VERSION ""

NS_ :

BS_:

BU_:
VAL_TABLE_ Alternative_Fuel_Mode_Enumeratio 0 "Not_in_Use" 1 "Flex_Fuel" 2 "Secondary_Fuel" ;
VAL_TABLE_ Warning_Source_Enumeration 23 "Exhaust_Temperature_Diagnostic" 35 "Boost_Control_Diagnostic" 36 "Coolant_Pressure_Sensor_Diagnostic" 21 "Exhaust_Lambda_Bank_1_Collector_Diagnostic" 24 "Throttle_Pedal_Sensor_Diagnostic" 25 "Throttle_Position_Sensor_Diagnostic" 26 "Throttle_Servo_Bank_1_Position_Sensor_Diagnostic" 27 "Throttle_Servo_Bank_2_Position_Sensor_Diagnostic" 37 "Inlet_Camshaft_Bank_1_Position_Diagnostic" 60 "Fuel_Cylinder_8_Secondary_Pin_Diagnostic" 64 "Fuel_Cylinder_12_Secondary_Pin_Diagnostic" 52 "Fuel_Cylinder_12_Primary_Pin_Diagnostic" 66 "CAN_Bus_2_Diagnostic" 65 "CAN_Bus_1_Diagnostic" 63 "Fuel_Cylinder_11_Secondary_Pin_Diagnostic" 38 "Inlet_Camshaft_Bank_2_Position_Diagnostic" 62 "Fuel_Cylinder_10_Secondary_Pin_Diagnostic" 30 "Fuel_Temperature_Sensor_Diagnostic" 17 "Brake_Vacuum_Pressure_Sensor_Diagnostic" 59 "Fuel_Cylinder_7_Secondary_Pin_Diagnostic" 18 "Inlet_Air_Temperature_Sensor_Diagnostic" 19 "Engine_Crankcase_Pressure_Sensor_Diagnostic" 20 "Engine_Oil_Temperature_Sensor_Diagnostic" 56 "Fuel_Cylinder_4_Secondary_Pin_Diagnostic" 48 "Fuel_Cylinder_8_Primary_Pin_Diagnostic" 49 "Fuel_Cylinder_9_Primary_Pin_Diagnostic" 45 "Fuel_Cylinder_5_Primary_Pin_Diagnostic" 50 "Fuel_Cylinder_10_Primary_Pin_Diagnostic" 51 "Fuel_Cylinder_11_Primary_Pin_Diagnostic" 57 "Fuel_Cylinder_5_Secondary_Pin_Diagnostic" 58 "Fuel_Cylinder_6_Secondary_Pin_Diagnostic" 14 "Engine_Oil_Pressure_Sensor_Diagnostic" 11 "Coolant_Pressure_Warning" 13 "Inlet_Manifold_Pressure_Sensor_Diagnostic" 12 "Engine_Speed_Warning" 28 "Boost_Pressure_Sensor_Diagnostic" 39 "Exhaust_Camshaft_Bank_1_Position_Diagnostic" 67 "CAN_Bus_3_Diagnostic" 70 "GPS_Diagnostic" 41 "Fuel_Cylinder_1_Primary_Pin_Diagnostic" 42 "Fuel_Cylinder_2_Primary_Pin_Diagnostic" 43 "Fuel_Cylinder_3_Primary_Pin_Diagnostic" 44 "Fuel_Cylinder_4_Primary_Pin_Diagnostic" 33 "Throttle_Servo_Bank_1_Diagnostic" 34 "Throttle_Servo_Bank_2_Diagnostic" 32 "Fuel_Closed_Loop_Diagnostic" 31 "Ambient_Pressure_Sensor_Diagnostic" 53 "Fuel_Cylinder_1_Secondary_Pin_Diagnostic" 55 "Fuel_Cylinder_3_Secondary_Pin_Diagnostic" 22 "Exhaust_Lambda_Bank_2_Collector_Diagnostic" 0 "None" 16 "Fuel_Pressure_Sensor_Diagnostic" 54 "Fuel_Cylinder_2_Secondary_Pin_Diagnostic" 2 "Knock_Warning" 3 "Engine_Crankcase_Pressure_Warning" 4 "Fuel_Pressure_Warning" 6 "Coolant_Temperature_Warning" 7 "Inlet_Air_Temperature_Warning" 8 "Engine_Oil_Temperature_Warning" 61 "Fuel_Cylinder_9_Secondary_Pin_Diagnostic" 10 "Exhaust_Temperature_Warning" 9 "Exhaust_Lambda_Warning" 46 "Fuel_Cylinder_6_Primary_Pin_Diagnostic" 47 "Fuel_Cylinder_7_Primary_Pin_Diagnostic" 15 "Coolant_Temperature_Sensor_Diagnostic" 40 "Exhaust_Camshaft_Bank_2_Position_Diagnostic" 68 "RS232_Diagnostic" 69 "Engine_Speed_Reference_Diagnostic" 1 "Engine_Oil_Pressure_Warning" 71 "Engine_Speed_Reference_State" 72 "Vehicle_Acceleration_Lateral_Sensor_Diagnostic" 5 "Alternative_Fuel_Pressure_Warning" 29 "Fuel_Composition_Sensor_Diagnostic" ;
VAL_TABLE_ Engine_State_Enumeration 0 "Startup" 1 "Stop" 2 "Run" 3 "Crank" ;
VAL_TABLE_ Fuel_Pump_Relay_State_Enumeratio 0 "Off" 1 "On" 2 "Prime" 3 "Hold" 4 "Test" ;
VAL_TABLE_ Anti_Lag_State_Enumeration 1 "Armed" 0 "Disabled" 2 "Enabled" 3 "Recover" ;
VAL_TABLE_ Mode_Enumeration 0 "Disabled" 1 "Enabled" ;
VAL_TABLE_ Boost_Aim_State_Enumeration 0 "Normal" 1 "Anti_Lag" 2 "Launch" ;
VAL_TABLE_ Engine_Overrun_State_Enumeration 0 "Disabled" 1 "Retard_Ignition" 2 "Enabled" 3 "Advance_Ignition" ;
VAL_TABLE_ Knock_State_Enumeration 0 "Disabled" 1 "Enabled" 2 "Transient" ;
VAL_TABLE_ Throttle_Aim_State_Enumeration 5 "Test" 1 "Idle" 0 "Pedal" 2 "Anti_Lag" 3 "Throttle_Limit" 4 "Gear_Shift" ;
VAL_TABLE_ Fuel_Closed_Loop_State_Enumerati -1 "Fault" 0 "Disabled" 1 "Shutdown" 2 "Wait" 3 "Sample" ;
VAL_TABLE_ Reference_State 0 "Open" 1 "Initialise" 2 "Stall" 3 "First Edge" 4 "First Period" 5 "Search" 6 "Pattern Lock" 7 "Cycle Lock" 8 "Error" 9 "Exit" 10 "Test" ;
VAL_TABLE_ Gear_Enumeration -2 "Default" -1 "Reverse" 0 "Neutral" 1 "First" 2 "Second" 3 "Third" 4 "Fourth" 5 "Fifth" 6 "Sixth" 7 "Seventh" ;
VAL_TABLE_ Fuel_State_Enumeration 5 "Cut_Cylinder_2_Test" 1 "Enabled" 2 "Cut_Bank_1_Test" 3 "Cut_Bank_2_Test" 4 "Cut_Cylinder_1_Test" 6 "Cut_Cylinder_3_Test" 7 "Cut_Cylinder_4_Test" 8 "Cut_Cylinder_5_Test" 9 "Cut_Cylinder_6_Test" 10 "Cut_Cylinder_7_Test" 11 "Cut_Cylinder_8_Test" 12 "Cut_Cylinder_9_Test" 13 "Cut_Cylinder_10_Test" 14 "Cut_Cylinder_11_Test" 15 "Cut_Cylinder_12_Test" 0 "Disabled" ;
VAL_TABLE_ Engine_Speed_Limit_State_Enumera 0 "Maximum" 2 "Throttle_Servo_Fault" 3 "Coolant_Temperature" 7 "Engine_Output_Test" 4 "Traction_Control" 5 "Launch" 6 "Vehicle_Speed_Limit" 1 "Engine_Load_Average" 8 "Anti_Lag" 10 "Coolant_Temperature_Warning" 11 "Coolant_Pressure_Warning" 12 "Engine_Speed_Warning" 13 "Engine_Oil_Temperature_Warning" 14 "Engine_Oil_Pressure_Warning" 15 "Engine_Crankcase_Pressure_Warning" 16 "Fuel_Pressure_Warning" 9 "Gear_Shift" 17 "Inlet_Air_Temperature_Warning" 18 "Exhaust_Lambda_Warning" 19 "Exhaust_Temperature_Warning" 20 "Experimental_Reference_Mode" 21 "Alternative_Fuel_Pressure_Warning" 22 "Boost_Servo_Fault" ;
VAL_TABLE_ Anti_Lag_Diagnostic_Enumeration 3 "Exhaust_Temperature_High" 2 "Time_Limit" 4 "Coolant_Temperature_High" 0 "Not_in_Use" 1 "OK" ;
VAL_TABLE_ Launch_Diagnostic_Enumeration 0 "Not_in_Use" 1 "OK" 2 "Exhaust_Temperature_High" 3 "Coolant_Temperature_High" ;
VAL_TABLE_ Boost_Control_Diagnostic_Enumera -1 "Maximum" 0 "Not_in_Use" 1 "Off" 2 "Active" 3 "Under_Margin" 4 "Over_Margin" 5 "Test" ;
VAL_TABLE_ Fuel_Cut_State_Enumeration 0 "None" 1 "Anti_Lag" 2 "Engine_Overrun" 3 "Flooded_Throttle_Position" 4 "Boost_Control_Diagnostic" 5 "Gear_Shift" 6 "Engine_Speed_Limit" ;
VAL_TABLE_ Fuel_Closed_Loop_Diagnostic_Enum -1 "Control_Failure" 0 "Sensor_Unavailable" 1 "OK" 2 "Single_Sensor" ;
VAL_TABLE_ Brake_State_Enumeration -1 "Sensor_Fault" 0 "Unknown" 1 "Off" 2 "On" ;
VAL_TABLE_ Nine_Position_Switch_State_Enume -1 "Default" 1 "One" 2 "Two" 3 "Three" 4 "Four" 5 "Five" 6 "Six" 7 "Seven" 8 "Eight" 9 "Nine" 0 "Zero" ;
VAL_TABLE_ Sensor_Diagnostic_Enumeration -3 "Communications_Timeout" -2 "Low_Fault" -1 "High_Fault" 0 "Not_in_Use" 1 "OK" 2 "Low_Warning" 3 "High_Warning" 4 "Translation_Minimum" 5 "Translation_Maximum" ;
VAL_TABLE_ Ignition_Timing_State_Enumeratio 3 "Limit_Advance" 4 "Limit_Retard" 0 "Normal" 2 "Check_Timing" 1 "Cranking" 7 "Launch" 5 "Idle" 6 "Engine_Overrun" 8 "Gear_Shift" 9 "Anti_Lag" ;
VAL_TABLE_ Ignition_Cut_State_Enumeration 0 "None" 1 "Anti_Lag" 2 "Gear_Shift" 3 "Engine_Speed_Limit" ;

BO_ 3221225472 VECTOR__INDEPENDENT_SIG_MSG: 0 Vector__XXX
 SG_ Steering_Angle_ADR : 0|16@0- (0.1,0) [0|0] "deg" Vector__XXX
 SG_ Wheel_Speed_Rear_Right_ADR : 0|16@0+ (0.1,0) [0|340] "km/h" Vector__XXX
 SG_ Wheel_Speed_Rear_Left_ADR : 0|16@0+ (0.1,0) [0|340] "km/h" Vector__XXX
 SG_ Wheel_Speed_Front_Right_ADR : 0|16@0+ (0.1,0) [0|340] "km/h" Vector__XXX
 SG_ Wheel_Speed_Front_Left_ADR : 0|16@0+ (0.1,0) [0|340] "km/h" Vector__XXX
 SG_ Brake_Pressure_Rear_ADR : 0|16@0+ (1,0) [0|65535] "kPa" Vector__XXX
 SG_ Brake_Pressure_Front_ADR : 0|16@0+ (1,0) [0|65535] "kPa" Vector__XXX
 SG_ Throttle_Position_ADR : 0|16@0+ (0.1,0) [0|100] "%" Vector__XXX
 SG_ Engine_Speed_ADR : 0|16@0+ (6,0) [0|393210] "RPM" Vector__XXX

BO_ 1697 M1_General_0x6A1: 8 Vector__XXX
 SG_ Auxillary_Output_5_Duty_Cycle : 7|16@0+ (0.1,0) [0|0] "%" Vector__XXX

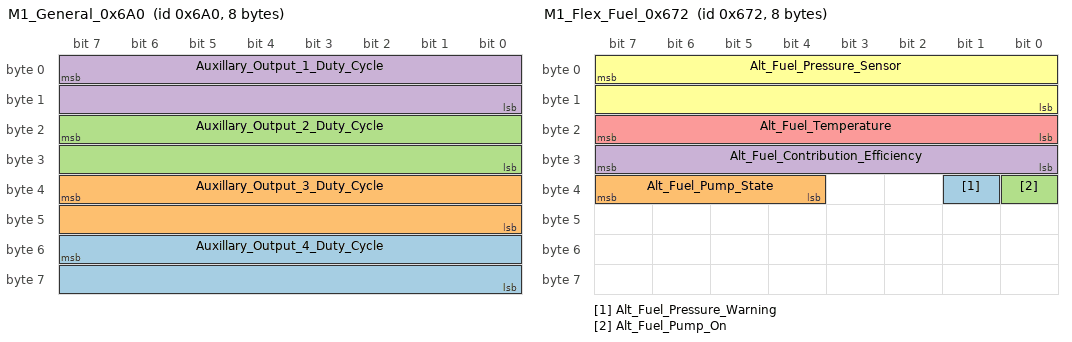
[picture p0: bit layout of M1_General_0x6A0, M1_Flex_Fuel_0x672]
BO_ 1696 M1_General_0x6A0: 8 Vector__XXX
 SG_ Auxillary_Output_4_Duty_Cycle : 55|16@0- (0.1,0) [0|0] "%" Vector__XXX
 SG_ Auxillary_Output_3_Duty_Cycle : 39|16@0- (0.1,0) [0|0] "%" Vector__XXX
 SG_ Auxillary_Output_2_Duty_Cycle : 23|16@0- (0.1,0) [0|0] "%" Vector__XXX
 SG_ Auxillary_Output_1_Duty_Cycle : 7|16@0- (0.1,0) [0|0] "%" Vector__XXX

BO_ 1650 M1_Flex_Fuel_0x672: 8 Vector__XXX
 SG_ Alt_Fuel_Pressure_Warning : 33|1@0+ (1,0) [0|1] "" Vector__XXX
 SG_ Alt_Fuel_Pump_State : 39|4@0- (1,0) [-8|7] "" Vector__XXX
 SG_ Alt_Fuel_Pump_On : 32|1@0+ (1,0) [0|1] "" Vector__XXX
 SG_ Alt_Fuel_Contribution_Efficiency : 31|8@0+ (1,0) [0|0] "%" Vector__XXX
 SG_ Alt_Fuel_Temperature : 23|8@0+ (1,-40) [-40|215] "C" Vector__XXX
 SG_ Alt_Fuel_Pressure_Sensor : 7|16@0+ (0.1,0) [0|1000] "kPa" Vector__XXX

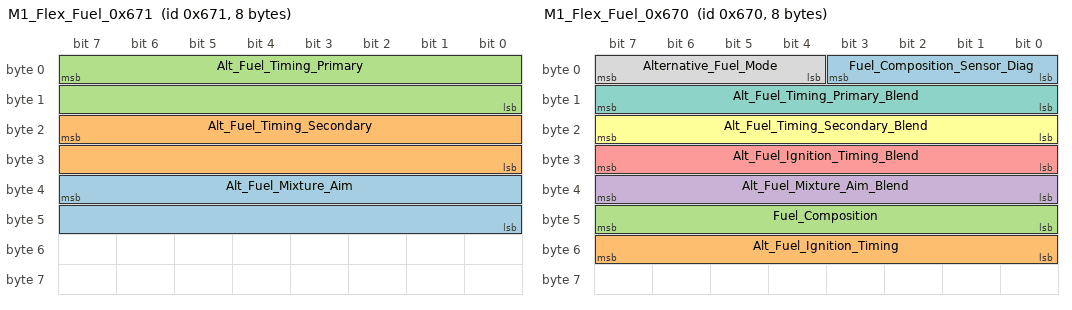
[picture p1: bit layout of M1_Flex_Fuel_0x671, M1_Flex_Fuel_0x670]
BO_ 1649 M1_Flex_Fuel_0x671: 8 Vector__XXX
 SG_ Alt_Fuel_Mixture_Aim : 39|16@0+ (0.01,0) [0|2] "LA" Vector__XXX
 SG_ Alt_Fuel_Timing_Secondary : 23|16@0- (0.1,0) [-720|720] "deg" Vector__XXX
 SG_ Alt_Fuel_Timing_Primary : 7|16@0- (0.1,0) [-720|720] "deg" Vector__XXX

BO_ 1648 M1_Flex_Fuel_0x670: 8 Vector__XXX
 SG_ Fuel_Composition_Sensor_Diag : 3|4@0- (1,0) [-8|7] "" Vector__XXX
 SG_ Alt_Fuel_Ignition_Timing : 55|8@0- (0.5,0) [0|0] "deg" Vector__XXX
 SG_ Fuel_Composition : 47|8@0+ (1,0) [0|0] "%" Vector__XXX
 SG_ Alt_Fuel_Mixture_Aim_Blend : 39|8@0+ (1,0) [0|0] "%" Vector__XXX
 SG_ Alt_Fuel_Ignition_Timing_Blend : 31|8@0+ (1,0) [0|0] "%" Vector__XXX
 SG_ Alt_Fuel_Timing_Secondary_Blend : 23|8@0+ (1,0) [0|0] "%" Vector__XXX
 SG_ Alt_Fuel_Timing_Primary_Blend : 15|8@0+ (1,0) [0|0] "%" Vector__XXX
 SG_ Alternative_Fuel_Mode : 7|4@0- (1,0) [0|0] "" Vector__XXX

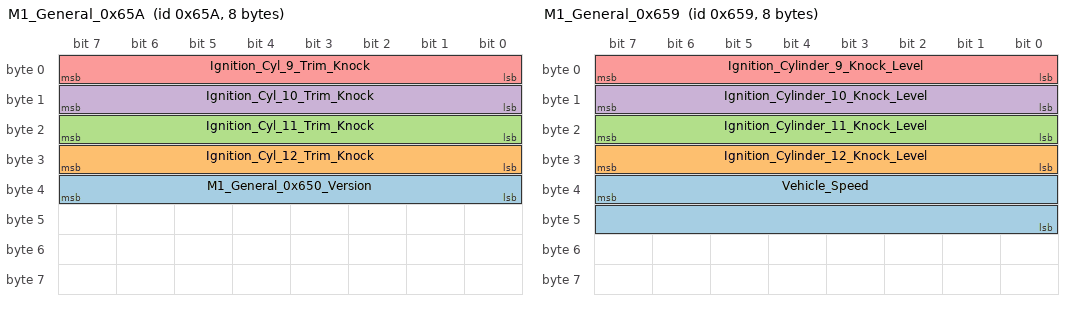
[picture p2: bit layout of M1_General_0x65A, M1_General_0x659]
BO_ 1626 M1_General_0x65A: 8 Vector__XXX
 SG_ M1_General_0x650_Version : 39|8@0+ (1,0) [0|0] "" Vector__XXX
 SG_ Ignition_Cyl_12_Trim_Knock : 31|8@0+ (0.1,0) [0|25.5] "deg" Vector__XXX
 SG_ Ignition_Cyl_11_Trim_Knock : 23|8@0+ (0.1,0) [0|25.5] "deg" Vector__XXX
 SG_ Ignition_Cyl_10_Trim_Knock : 15|8@0+ (0.1,0) [0|25.5] "deg" Vector__XXX
 SG_ Ignition_Cyl_9_Trim_Knock : 7|8@0+ (0.1,0) [0|25.5] "deg" Vector__XXX

BO_ 1625 M1_General_0x659: 8 Vector__XXX
 SG_ Vehicle_Speed : 39|16@0+ (0.1,0) [0|6553.5] "km/h" Vector__XXX
 SG_ Ignition_Cylinder_12_Knock_Level : 31|8@0+ (1,0) [0|200] "%" Vector__XXX
 SG_ Ignition_Cylinder_11_Knock_Level : 23|8@0+ (1,0) [0|200] "%" Vector__XXX
 SG_ Ignition_Cylinder_10_Knock_Level : 15|8@0+ (1,0) [0|200] "%" Vector__XXX
 SG_ Ignition_Cylinder_9_Knock_Level : 7|8@0+ (1,0) [0|200] "%" Vector__XXX

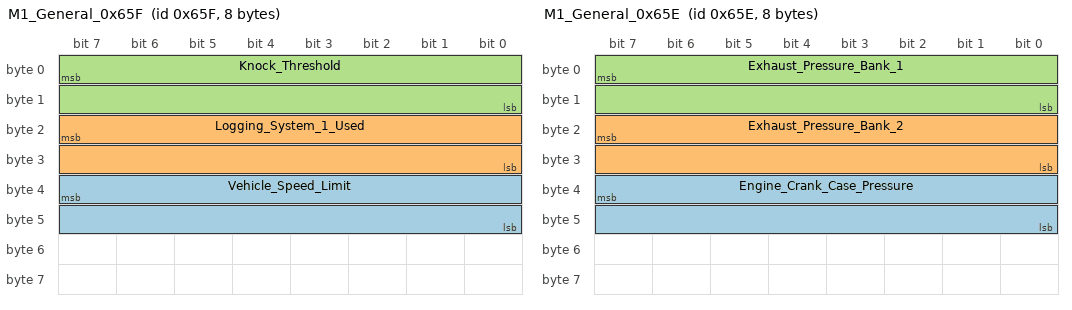
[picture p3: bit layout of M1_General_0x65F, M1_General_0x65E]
BO_ 1631 M1_General_0x65F: 8 Vector__XXX
 SG_ Vehicle_Speed_Limit : 39|16@0+ (0.1,0) [0|6553.5] "km/h" Vector__XXX
 SG_ Logging_System_1_Used : 23|16@0+ (0.1,0) [0|0] "%" Vector__XXX
 SG_ Knock_Threshold : 7|16@0+ (0.1,0) [0|200] "%" Vector__XXX

BO_ 1630 M1_General_0x65E: 8 Vector__XXX
 SG_ Engine_Crank_Case_Pressure : 39|16@0- (0.1,0) [0|24000] "kPa" Vector__XXX
 SG_ Exhaust_Pressure_Bank_2 : 23|16@0- (0.1,0) [0|24000] "kPa" Vector__XXX
 SG_ Exhaust_Pressure_Bank_1 : 7|16@0- (0.1,0) [0|24000] "kPa" Vector__XXX

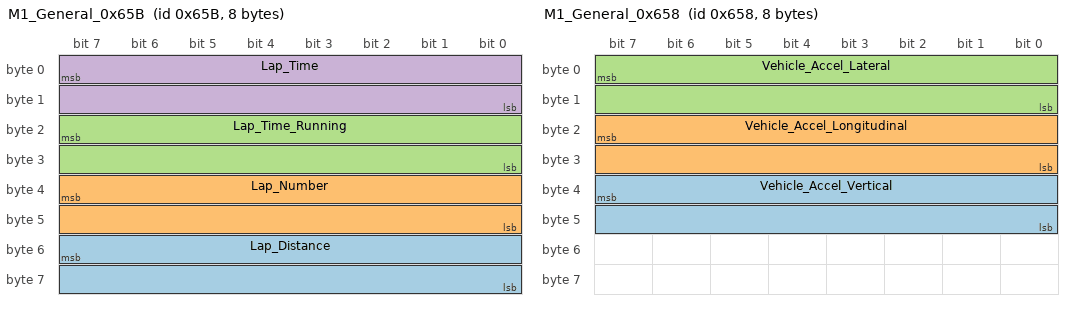
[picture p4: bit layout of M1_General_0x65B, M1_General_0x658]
BO_ 1627 M1_General_0x65B: 8 Vector__XXX
 SG_ Lap_Distance : 55|16@0+ (1,0) [0|0] "m" Vector__XXX
 SG_ Lap_Number : 39|16@0+ (1,0) [0|0] "" Vector__XXX
 SG_ Lap_Time_Running : 23|16@0+ (0.01,0) [0|0] "s" Vector__XXX
 SG_ Lap_Time : 7|16@0+ (0.01,0) [0|0] "s" Vector__XXX

BO_ 1624 M1_General_0x658: 8 Vector__XXX
 SG_ Vehicle_Accel_Vertical : 39|16@0- (0.001,0) [0|0] "g" Vector__XXX
 SG_ Vehicle_Accel_Longitudinal : 23|16@0- (0.001,0) [0|0] "g" Vector__XXX
 SG_ Vehicle_Accel_Lateral : 7|16@0- (0.001,0) [0|0] "g" Vector__XXX

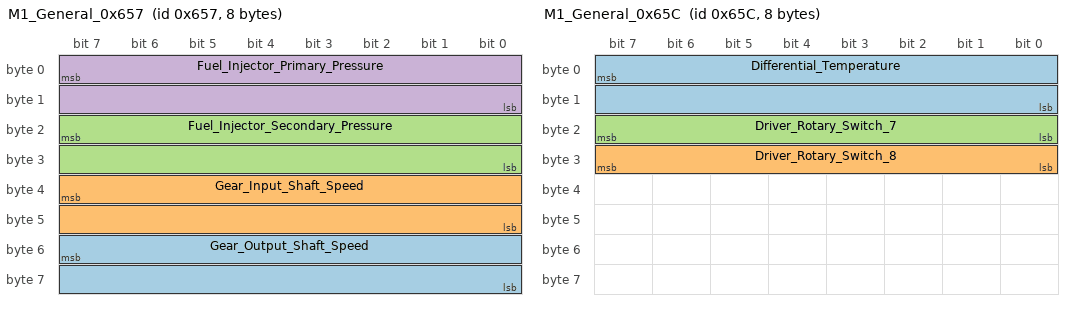
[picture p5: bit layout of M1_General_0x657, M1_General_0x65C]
BO_ 1623 M1_General_0x657: 8 Vector__XXX
 SG_ Gear_Output_Shaft_Speed : 55|16@0+ (1,0) [0|0] "RPM" Vector__XXX
 SG_ Gear_Input_Shaft_Speed : 39|16@0+ (1,0) [0|0] "RPM" Vector__XXX
 SG_ Fuel_Injector_Secondary_Pressure : 23|16@0- (0.1,0) [0|24000] "kPa" Vector__XXX
 SG_ Fuel_Injector_Primary_Pressure : 7|16@0- (0.1,0) [0|24000] "kPa" Vector__XXX

BO_ 1628 M1_General_0x65C: 8 Vector__XXX
 SG_ Differential_Temperature : 7|16@0- (0.1,0) [-30|160] "C" Vector__XXX
 SG_ Driver_Rotary_Switch_8 : 31|8@0- (1,0) [0|0] "" Vector__XXX
 SG_ Driver_Rotary_Switch_7 : 23|8@0- (1,0) [0|0] "" Vector__XXX

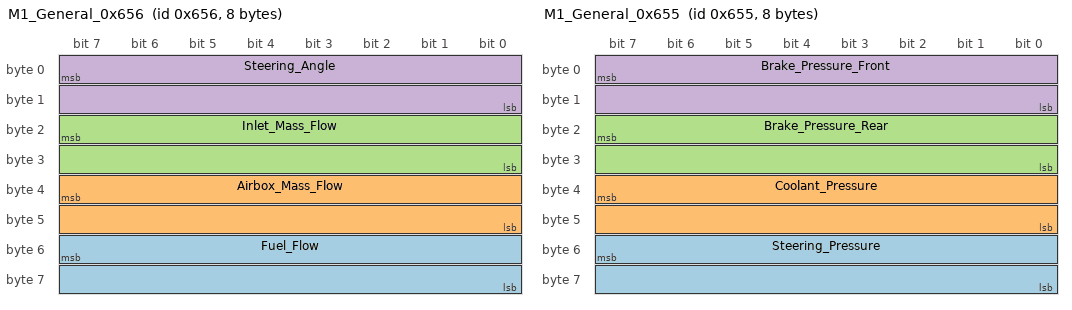
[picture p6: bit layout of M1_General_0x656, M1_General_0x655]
BO_ 1622 M1_General_0x656: 8 Vector__XXX
 SG_ Fuel_Flow : 55|16@0+ (0.01,0) [0|0] "ml/s" Vector__XXX
 SG_ Airbox_Mass_Flow : 39|16@0+ (0.1,0) [0|0] "g/s" Vector__XXX
 SG_ Inlet_Mass_Flow : 23|16@0+ (0.1,0) [0|0] "g/s" Vector__XXX
 SG_ Steering_Angle : 7|16@0- (0.1,0) [0|0] "deg" Vector__XXX

BO_ 1621 M1_General_0x655: 8 Vector__XXX
 SG_ Steering_Pressure : 55|16@0- (1,0) [-32768|32767] "kPa" Vector__XXX
 SG_ Coolant_Pressure : 39|16@0- (0.1,0) [-3276.8|3276.7] "kPa" Vector__XXX
 SG_ Brake_Pressure_Rear : 23|16@0- (1,0) [-32768|32767] "kPa" Vector__XXX
 SG_ Brake_Pressure_Front : 7|16@0- (1,0) [-32768|32767] "kPa" Vector__XXX

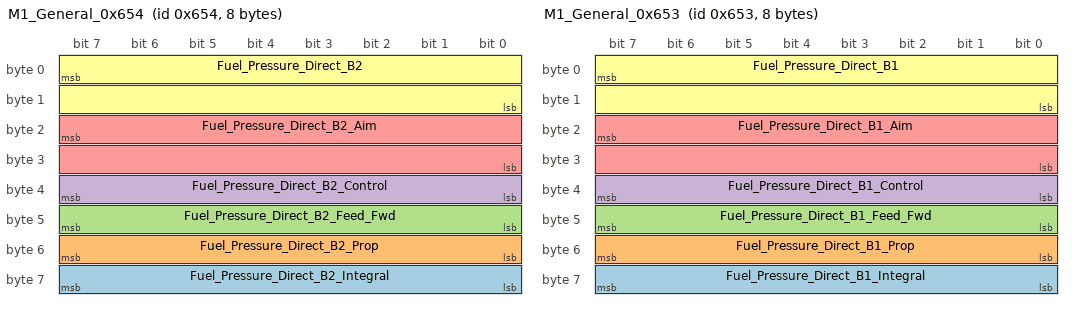
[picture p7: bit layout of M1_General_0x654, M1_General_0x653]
BO_ 1620 M1_General_0x654: 8 Vector__XXX
 SG_ Fuel_Pressure_Direct_B2_Integral : 63|8@0- (1,0) [-128|127] "%" Vector__XXX
 SG_ Fuel_Pressure_Direct_B2_Prop : 55|8@0- (1,0) [-128|127] "%" Vector__XXX
 SG_ Fuel_Pressure_Direct_B2_Feed_Fwd : 47|8@0- (1,0) [-128|127] "%" Vector__XXX
 SG_ Fuel_Pressure_Direct_B2_Control : 39|8@0+ (0.5,0) [0|100] "%" Vector__XXX
 SG_ Fuel_Pressure_Direct_B2_Aim : 23|16@0+ (1,0) [0|24000] "kPa" Vector__XXX
 SG_ Fuel_Pressure_Direct_B2 : 7|16@0+ (1,0) [0|24000] "kPa" Vector__XXX

BO_ 1619 M1_General_0x653: 8 Vector__XXX
 SG_ Fuel_Pressure_Direct_B1_Integral : 63|8@0- (1,0) [-128|127] "%" Vector__XXX
 SG_ Fuel_Pressure_Direct_B1_Prop : 55|8@0- (1,0) [-128|127] "%" Vector__XXX
 SG_ Fuel_Pressure_Direct_B1_Feed_Fwd : 47|8@0- (1,0) [-128|127] "%" Vector__XXX
 SG_ Fuel_Pressure_Direct_B1_Control : 39|8@0+ (0.5,0) [0|100] "%" Vector__XXX
 SG_ Fuel_Pressure_Direct_B1_Aim : 23|16@0+ (1,0) [0|24000] "kPa" Vector__XXX
 SG_ Fuel_Pressure_Direct_B1 : 7|16@0+ (1,0) [0|24000] "kPa" Vector__XXX

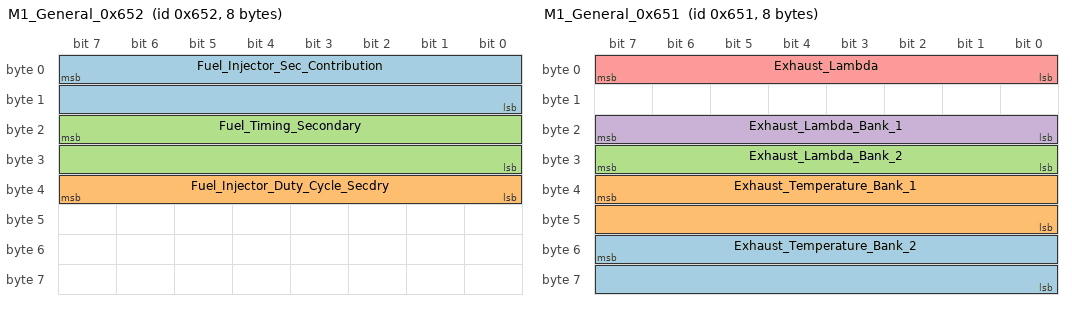
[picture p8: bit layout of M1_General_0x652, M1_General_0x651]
BO_ 1618 M1_General_0x652: 8 Vector__XXX
 SG_ Fuel_Injector_Sec_Contribution : 7|16@0+ (0.1,0) [0|100] "%" Vector__XXX
 SG_ Fuel_Injector_Duty_Cycle_Secdry : 39|8@0+ (1,0) [0|100] "%" Vector__XXX
 SG_ Fuel_Timing_Secondary : 23|16@0- (0.1,0) [-720|720] "deg" Vector__XXX

BO_ 1617 M1_General_0x651: 8 Vector__XXX
 SG_ Exhaust_Temperature_Bank_2 : 55|16@0+ (0.1,0) [0|1200] "C" Vector__XXX
 SG_ Exhaust_Temperature_Bank_1 : 39|16@0+ (0.1,0) [0|1200] "C" Vector__XXX
 SG_ Exhaust_Lambda_Bank_2 : 31|8@0+ (0.01,0) [0|0] "LA" Vector__XXX
 SG_ Exhaust_Lambda_Bank_1 : 23|8@0+ (0.01,0) [0|0] "LA" Vector__XXX
 SG_ Exhaust_Lambda : 7|8@0+ (0.01,0) [0|0] "LA" Vector__XXX

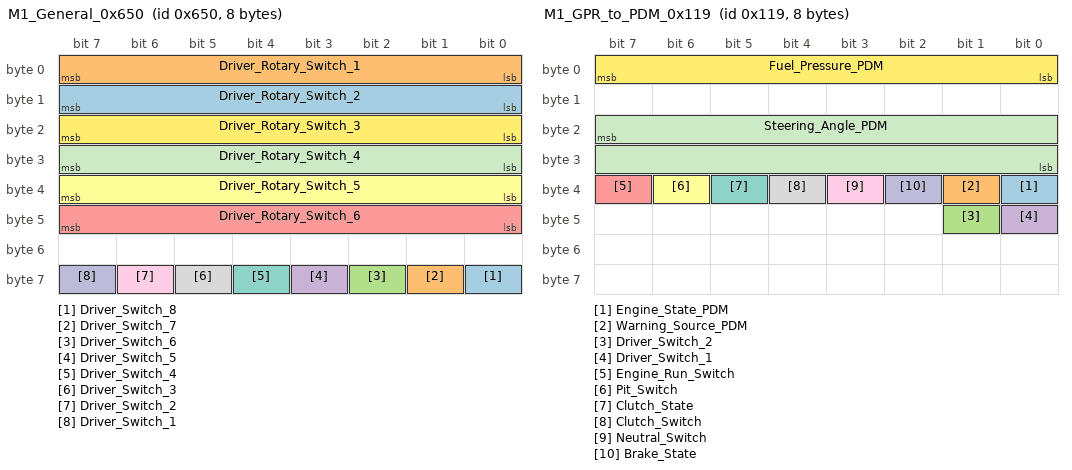
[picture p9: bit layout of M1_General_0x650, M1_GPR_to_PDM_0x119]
BO_ 1616 M1_General_0x650: 8 Vector__XXX
 SG_ Driver_Switch_8 : 56|1@0+ (1,0) [0|0] "" Vector__XXX
 SG_ Driver_Switch_7 : 57|1@0+ (1,0) [0|0] "" Vector__XXX
 SG_ Driver_Switch_6 : 58|1@0+ (1,0) [0|0] "" Vector__XXX
 SG_ Driver_Switch_5 : 59|1@0+ (1,0) [0|0] "" Vector__XXX
 SG_ Driver_Rotary_Switch_6 : 47|8@0- (1,0) [0|0] "" Vector__XXX
 SG_ Driver_Rotary_Switch_5 : 39|8@0- (1,0) [0|0] "" Vector__XXX
 SG_ Driver_Switch_4 : 60|1@0+ (1,0) [0|0] "" Vector__XXX
 SG_ Driver_Switch_3 : 61|1@0+ (1,0) [0|0] "" Vector__XXX
 SG_ Driver_Switch_2 : 62|1@0+ (1,0) [0|1] "" Vector__XXX
 SG_ Driver_Switch_1 : 63|1@0+ (1,0) [0|1] "" Vector__XXX
 SG_ Driver_Rotary_Switch_4 : 31|8@0- (1,0) [0|0] "" Vector__XXX
 SG_ Driver_Rotary_Switch_3 : 23|8@0- (1,0) [0|0] "" Vector__XXX
 SG_ Driver_Rotary_Switch_2 : 15|8@0- (1,0) [0|0] "" Vector__XXX
 SG_ Driver_Rotary_Switch_1 : 7|8@0- (1,0) [0|0] "" Vector__XXX

BO_ 1152 M1_LTC_Enable: 8 Vector__XXX

BO_ 282 M1_GPR_to_PDM_0x11A: 3 Vector__XXX
 SG_ PDM_Byte_2_Mask_80 : 23|1@0+ (1,0) [0|0] "" Vector__XXX
 SG_ PDM_Byte_2_Mask_40 : 22|1@0+ (1,0) [0|0] "" Vector__XXX
 SG_ PDM_Byte_2_Mask_20 : 21|1@0+ (1,0) [0|0] "" Vector__XXX
 SG_ PDM_Byte_2_Mask_10 : 20|1@0+ (1,0) [0|0] "" Vector__XXX
 SG_ PDM_Byte_2_Mask_08 : 19|1@0+ (1,0) [0|0] "" Vector__XXX
 SG_ PDM_Byte_2_Mask_04 : 18|1@0+ (1,0) [0|0] "" Vector__XXX
 SG_ PDM_Byte_2_Mask_02 : 17|1@0+ (1,0) [0|0] "" Vector__XXX
 SG_ PDM_Byte_2_Mask_01 : 16|1@0+ (1,0) [0|0] "" Vector__XXX
 SG_ PDM_Byte_1_Mask_80 : 15|1@0+ (1,0) [0|0] "" Vector__XXX
 SG_ PDM_Byte_1_Mask_40 : 14|1@0+ (1,0) [0|0] "" Vector__XXX
 SG_ PDM_Byte_1_Mask_20 : 13|1@0+ (1,0) [0|0] "" Vector__XXX
 SG_ PDM_Byte_1_Mask_10 : 12|1@0+ (1,0) [0|0] "" Vector__XXX
 SG_ PDM_Byte_1_Mask_08 : 11|1@0+ (1,0) [0|0] "" Vector__XXX
 SG_ PDM_Byte_1_Mask_04 : 10|1@0+ (1,0) [0|0] "" Vector__XXX
 SG_ PDM_Byte_1_Mask_02 : 9|1@0+ (1,0) [0|0] "" Vector__XXX
 SG_ PDM_Byte_1_Mask_01 : 8|1@0+ (1,0) [0|0] "" Vector__XXX
 SG_ PDM_Byte_0_Mask_80 : 7|1@0+ (1,0) [0|0] "" Vector__XXX
 SG_ PDM_Byte_0_Mask_40 : 6|1@0+ (1,0) [0|0] "" Vector__XXX
 SG_ PDM_Byte_0_Mask_20 : 5|1@0+ (1,0) [0|0] "" Vector__XXX
 SG_ PDM_Byte_0_Mask_10 : 4|1@0+ (1,0) [0|0] "" Vector__XXX
 SG_ PDM_Byte_0_Mask_08 : 3|1@0+ (1,0) [0|0] "" Vector__XXX
 SG_ PDM_Byte_0_Mask_04 : 2|1@0+ (1,0) [0|0] "" Vector__XXX
 SG_ PDM_Byte_0_Mask_02 : 1|1@0+ (1,0) [0|0] "" Vector__XXX
 SG_ PDM_Byte_0_Mask_01 : 0|1@0+ (1,0) [0|0] "" Vector__XXX

BO_ 281 M1_GPR_to_PDM_0x119: 8 Vector__XXX
 SG_ Engine_State_PDM : 32|1@0+ (1,0) [0|1] "" Vector__XXX
 SG_ Warning_Source_PDM : 33|1@0+ (1,0) [0|1] "" Vector__XXX
 SG_ Driver_Switch_2 : 41|1@0+ (1,0) [0|1] "" Vector__XXX
 SG_ Driver_Switch_1 : 40|1@0+ (1,0) [0|1] "" Vector__XXX
 SG_ Engine_Run_Switch : 39|1@0+ (1,0) [0|1] "" Vector__XXX
 SG_ Pit_Switch : 38|1@0+ (1,0) [0|1] "" Vector__XXX
 SG_ Clutch_State : 37|1@0+ (1,0) [0|1] "" Vector__XXX
 SG_ Clutch_Switch : 36|1@0+ (1,0) [0|1] "" Vector__XXX
 SG_ Neutral_Switch : 35|1@0+ (1,0) [0|1] "" Vector__XXX
 SG_ Brake_State : 34|1@0+ (1,0) [0|1] "" Vector__XXX
 SG_ Steering_Angle_PDM : 23|16@0- (0.1,0) [-3276|3276] "deg" Vector__XXX
 SG_ Fuel_Pressure_PDM : 7|8@0+ (10,0) [0|2550] "kPa" Vector__XXX

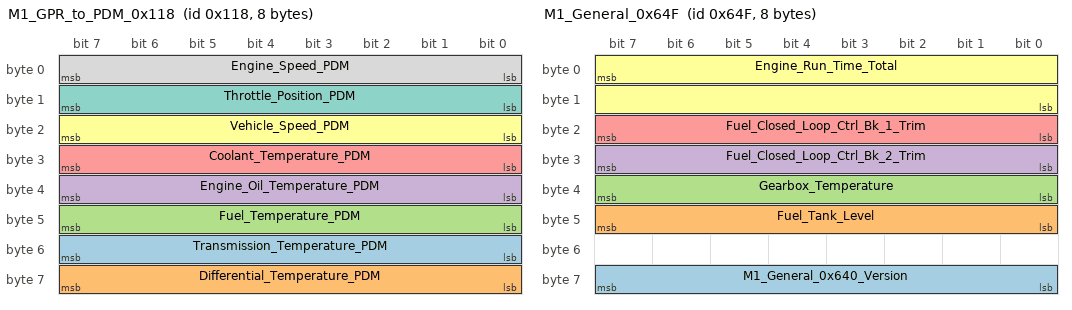
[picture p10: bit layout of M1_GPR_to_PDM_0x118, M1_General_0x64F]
BO_ 280 M1_GPR_to_PDM_0x118: 8 Vector__XXX
 SG_ Transmission_Temperature_PDM : 55|8@0+ (1,0) [0|255] "C" Vector__XXX
 SG_ Differential_Temperature_PDM : 63|8@0+ (1,0) [0|255] "C" Vector__XXX
 SG_ Fuel_Temperature_PDM : 47|8@0+ (1,0) [0|255] "C" Vector__XXX
 SG_ Engine_Oil_Temperature_PDM : 39|8@0+ (1,0) [0|255] "C" Vector__XXX
 SG_ Coolant_Temperature_PDM : 31|8@0+ (1,0) [0|255] "C" Vector__XXX
 SG_ Vehicle_Speed_PDM : 23|8@0+ (1,0) [0|255] "km/h" Vector__XXX
 SG_ Throttle_Position_PDM : 15|8@0+ (1,0) [0|255] "%" Vector__XXX
 SG_ Engine_Speed_PDM : 7|8@0+ (100,0) [0|25500] "RPM" Vector__XXX

BO_ 1615 M1_General_0x64F: 8 Vector__XXX
 SG_ M1_General_0x640_Version : 63|8@0+ (1,0) [0|0] "" Vector__XXX
 SG_ Fuel_Tank_Level : 47|8@0+ (1,0) [0|255] "l" Vector__XXX
 SG_ Gearbox_Temperature : 39|8@0+ (1,-40) [-40|215] "C" Vector__XXX
 SG_ Fuel_Closed_Loop_Ctrl_Bk_2_Trim : 31|8@0+ (0.005,0) [0|1.275] "ratio" Vector__XXX
 SG_ Fuel_Closed_Loop_Ctrl_Bk_1_Trim : 23|8@0+ (0.005,0) [0|1.275] "ratio" Vector__XXX
 SG_ Engine_Run_Time_Total : 7|16@0+ (0.1,0) [0|6553.5] "hour" Vector__XXX

BO_ 1614 M1_General_0x64E: 8 Vector__XXX
 SG_ Driver_Wheel_Circumference_Sw : 43|1@0+ (1,0) [0|0] "" Vector__XXX
 SG_ Driver_Trans_Brake_Bump_Sw : 44|1@0+ (1,0) [0|0] "" Vector__XXX
 SG_ Driver_Throttle_Pedal_Trans_Sw : 45|1@0+ (1,0) [0|0] "" Vector__XXX
 SG_ Driver_Race_Time_Rest_Sw : 46|1@0+ (1,0) [0|0] "" Vector__XXX
 SG_ Driver_Ign_Timing_Main_Sw : 47|1@0+ (1,0) [0|0] "" Vector__XXX
 SG_ Driver_Gear_Shift_Sw : 33|1@0+ (1,0) [0|0] "" Vector__XXX
 SG_ Driver_Gear_Shift_Auto_Drag_Sw : 32|1@0+ (1,0) [0|0] "" Vector__XXX
 SG_ Driver_Fuel_Mix_Aim_Main_Sw : 34|1@0+ (1,0) [0|0] "" Vector__XXX
 SG_ Driver_Eng_Spd_Limit_Max_Sw : 35|1@0+ (1,0) [0|0] "" Vector__XXX
 SG_ Driver_Boost_Limit_Disable_Sw : 36|1@0+ (1,0) [0|0] "" Vector__XXX
 SG_ Driver_Aux_Time_Switch : 37|1@0+ (1,0) [0|0] "" Vector__XXX
 SG_ Driver_Anti_Lag_Mode_Sw : 39|2@0- (1,0) [0|0] "" Vector__XXX
 SG_ Fuel_Cut_State : 11|4@0+ (1,0) [0|15] "" Vector__XXX
 SG_ Brake_State : 27|1@0+ (1,0) [0|1] "" Vector__XXX
 SG_ Neutral_Switch : 24|1@0+ (1,0) [0|1] "" Vector__XXX
 SG_ Engine_Run_Switch : 25|1@0+ (1,0) [0|1] "" Vector__XXX
 SG_ Anti_Lag_Switch : 26|1@0+ (1,0) [0|1] "" Vector__XXX
 SG_ Traction_Switch : 28|1@0+ (1,0) [0|1] "" Vector__XXX
 SG_ Launch_Switch : 29|1@0+ (1,0) [0|1] "" Vector__XXX
 SG_ Pit_Switch : 30|1@0+ (1,0) [0|1] "" Vector__XXX
 SG_ Engine_Oil_Pressure_Low_Switch : 31|1@0+ (1,0) [0|1] "" Vector__XXX
 SG_ Fuel_Closed_Loop_Diagnostic : 23|4@0- (1,0) [-8|7] "" Vector__XXX
 SG_ Boost_Control_Diagnostic : 15|4@0- (1,0) [-8|7] "" Vector__XXX
 SG_ Launch_Diagnostic : 3|4@0- (1,0) [-8|7] "" Vector__XXX
 SG_ Anti_Lag_Diagnostic : 7|4@0- (1,0) [-8|7] "" Vector__XXX

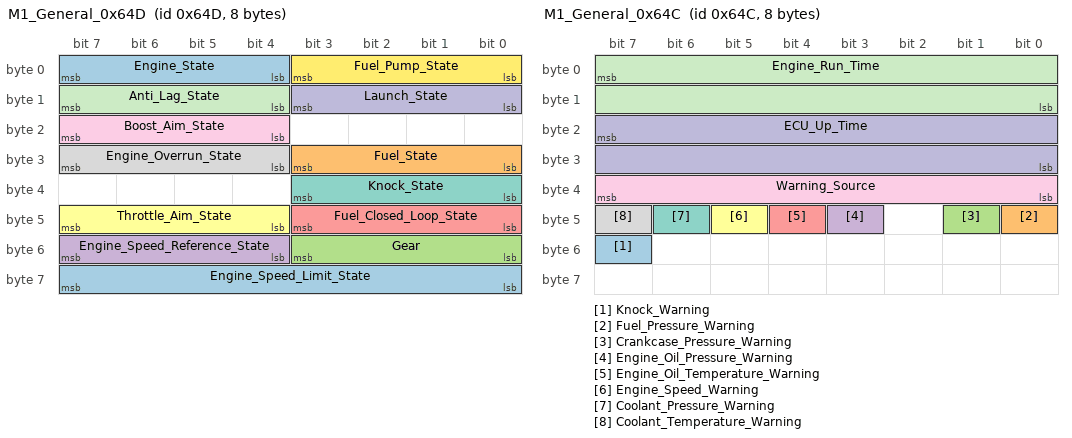
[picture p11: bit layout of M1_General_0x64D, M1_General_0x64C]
BO_ 1613 M1_General_0x64D: 8 Vector__XXX
 SG_ Engine_Speed_Limit_State : 63|8@0+ (1,0) [0|255] "" Vector__XXX
 SG_ Fuel_State : 27|4@0+ (1,0) [0|15] "" Vector__XXX
 SG_ Gear : 51|4@0- (1,0) [-8|7] "" Vector__XXX
 SG_ Engine_Speed_Reference_State : 55|4@0+ (1,0) [0|15] "" Vector__XXX
 SG_ Fuel_Closed_Loop_State : 43|4@0+ (1,0) [0|15] "" Vector__XXX
 SG_ Throttle_Aim_State : 47|4@0+ (1,0) [0|15] "" Vector__XXX
 SG_ Knock_State : 35|4@0+ (1,0) [0|15] "" Vector__XXX
 SG_ Engine_Overrun_State : 31|4@0+ (1,0) [0|15] "" Vector__XXX
 SG_ Boost_Aim_State : 23|4@0+ (1,0) [0|15] "" Vector__XXX
 SG_ Launch_State : 11|4@0+ (1,0) [0|15] "" Vector__XXX
 SG_ Anti_Lag_State : 15|4@0+ (1,0) [0|15] "" Vector__XXX
 SG_ Fuel_Pump_State : 3|4@0+ (1,0) [0|15] "" Vector__XXX
 SG_ Engine_State : 7|4@0+ (1,0) [0|15] "" Vector__XXX

BO_ 1612 M1_General_0x64C: 8 Vector__XXX
 SG_ Knock_Warning : 55|1@0+ (1,0) [0|1] "" Vector__XXX
 SG_ Fuel_Pressure_Warning : 40|1@0+ (1,0) [0|1] "" Vector__XXX
 SG_ Crankcase_Pressure_Warning : 41|1@0+ (1,0) [0|1] "" Vector__XXX
 SG_ Engine_Oil_Pressure_Warning : 43|1@0+ (1,0) [0|1] "" Vector__XXX
 SG_ Engine_Oil_Temperature_Warning : 44|1@0+ (1,0) [0|1] "" Vector__XXX
 SG_ Engine_Speed_Warning : 45|1@0+ (1,0) [0|1] "" Vector__XXX
 SG_ Coolant_Pressure_Warning : 46|1@0+ (1,0) [0|1] "" Vector__XXX
 SG_ Coolant_Temperature_Warning : 47|1@0+ (1,0) [0|1] "" Vector__XXX
 SG_ Warning_Source : 39|8@0+ (1,0) [0|0] "" Vector__XXX
 SG_ ECU_Up_Time : 23|16@0+ (1,0) [0|65535] "s" Vector__XXX
 SG_ Engine_Run_Time : 7|16@0+ (1,0) [0|65535] "s" Vector__XXX

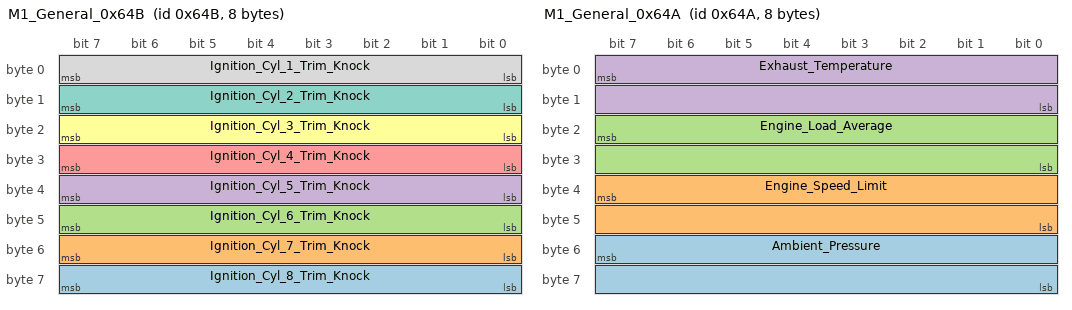
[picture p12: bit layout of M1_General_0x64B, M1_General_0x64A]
BO_ 1611 M1_General_0x64B: 8 Vector__XXX
 SG_ Ignition_Cyl_8_Trim_Knock : 63|8@0+ (0.1,0) [0|25.5] "deg" Vector__XXX
 SG_ Ignition_Cyl_7_Trim_Knock : 55|8@0+ (0.1,0) [0|25.5] "deg" Vector__XXX
 SG_ Ignition_Cyl_6_Trim_Knock : 47|8@0+ (0.1,0) [0|25.5] "deg" Vector__XXX
 SG_ Ignition_Cyl_5_Trim_Knock : 39|8@0+ (0.1,0) [0|25.5] "deg" Vector__XXX
 SG_ Ignition_Cyl_4_Trim_Knock : 31|8@0+ (0.1,0) [0|25.5] "deg" Vector__XXX
 SG_ Ignition_Cyl_3_Trim_Knock : 23|8@0+ (0.1,0) [0|25.5] "deg" Vector__XXX
 SG_ Ignition_Cyl_2_Trim_Knock : 15|8@0+ (0.1,0) [0|25.5] "deg" Vector__XXX
 SG_ Ignition_Cyl_1_Trim_Knock : 7|8@0+ (0.1,0) [0|25.5] "deg" Vector__XXX

BO_ 1610 M1_General_0x64A: 8 Vector__XXX
 SG_ Ambient_Pressure : 55|16@0- (0.1,0) [60|110] "kPa" Vector__XXX
 SG_ Engine_Speed_Limit : 39|16@0+ (1,0) [0|16000] "RPM" Vector__XXX
 SG_ Engine_Load_Average : 23|16@0+ (0.1,0) [0|100] "%" Vector__XXX
 SG_ Exhaust_Temperature : 7|16@0+ (0.1,0) [0|1200] "C" Vector__XXX

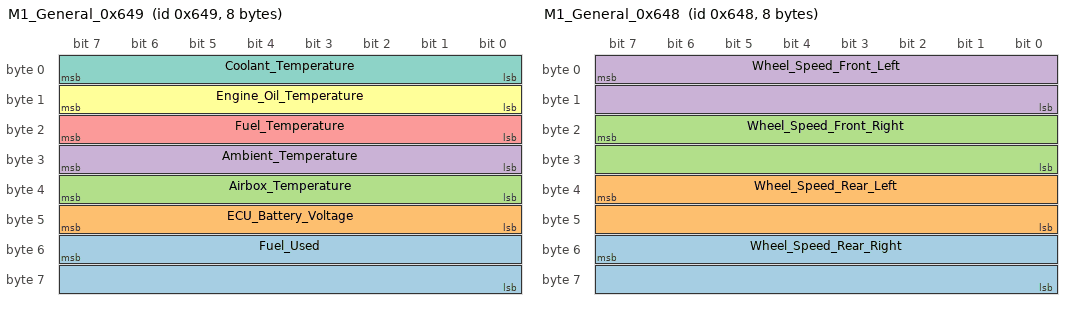
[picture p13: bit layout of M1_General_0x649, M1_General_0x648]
BO_ 1609 M1_General_0x649: 8 Vector__XXX
 SG_ Fuel_Used : 55|16@0+ (0.01,0) [0|655.35] "l" Vector__XXX
 SG_ ECU_Battery_Voltage : 47|8@0+ (0.1,0) [0|25.5] "V" Vector__XXX
 SG_ Airbox_Temperature : 39|8@0+ (1,-40) [-40|215] "C" Vector__XXX
 SG_ Ambient_Temperature : 31|8@0+ (1,-40) [-40|215] "C" Vector__XXX
 SG_ Fuel_Temperature : 23|8@0+ (1,-40) [-40|215] "C" Vector__XXX
 SG_ Engine_Oil_Temperature : 15|8@0+ (1,-40) [-40|215] "C" Vector__XXX
 SG_ Coolant_Temperature : 7|8@0+ (1,-40) [-40|215] "C" Vector__XXX

BO_ 1608 M1_General_0x648: 8 Vector__XXX
 SG_ Wheel_Speed_Rear_Right : 55|16@0+ (0.1,0) [0|340] "km/h" Vector__XXX
 SG_ Wheel_Speed_Rear_Left : 39|16@0+ (0.1,0) [0|340] "km/h" Vector__XXX
 SG_ Wheel_Speed_Front_Right : 23|16@0+ (0.1,0) [0|340] "km/h" Vector__XXX
 SG_ Wheel_Speed_Front_Left : 7|16@0+ (0.1,0) [0|340] "km/h" Vector__XXX

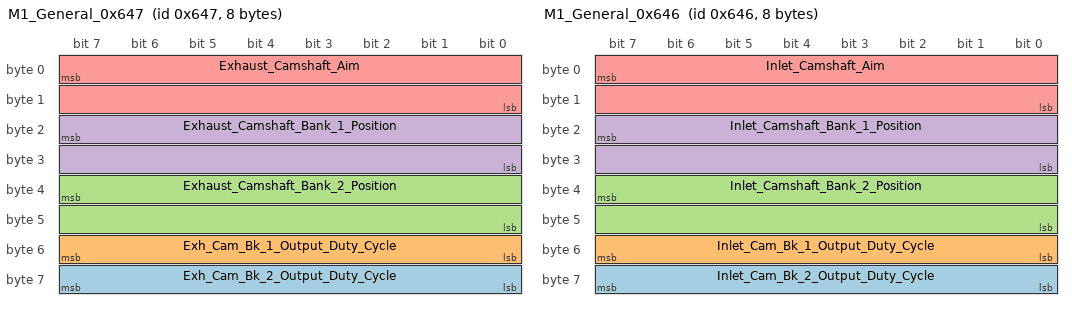
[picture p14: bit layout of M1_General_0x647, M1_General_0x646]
BO_ 1607 M1_General_0x647: 8 Vector__XXX
 SG_ Exh_Cam_Bk_2_Output_Duty_Cycle : 63|8@0+ (1,0) [0|100] "%" Vector__XXX
 SG_ Exh_Cam_Bk_1_Output_Duty_Cycle : 55|8@0+ (1,0) [0|100] "%" Vector__XXX
 SG_ Exhaust_Camshaft_Bank_2_Position : 39|16@0- (0.1,0) [-60|60] "deg" Vector__XXX
 SG_ Exhaust_Camshaft_Bank_1_Position : 23|16@0- (0.1,0) [-60|60] "deg" Vector__XXX
 SG_ Exhaust_Camshaft_Aim : 7|16@0- (0.1,0) [-60|60] "deg" Vector__XXX

BO_ 1606 M1_General_0x646: 8 Vector__XXX
 SG_ Inlet_Cam_Bk_2_Output_Duty_Cycle : 63|8@0+ (1,0) [0|100] "%" Vector__XXX
 SG_ Inlet_Cam_Bk_1_Output_Duty_Cycle : 55|8@0+ (1,0) [0|100] "%" Vector__XXX
 SG_ Inlet_Camshaft_Bank_2_Position : 39|16@0- (0.1,0) [-60|60] "deg" Vector__XXX
 SG_ Inlet_Camshaft_Bank_1_Position : 23|16@0- (0.1,0) [-60|60] "deg" Vector__XXX
 SG_ Inlet_Camshaft_Aim : 7|16@0- (0.1,0) [-60|60] "deg" Vector__XXX

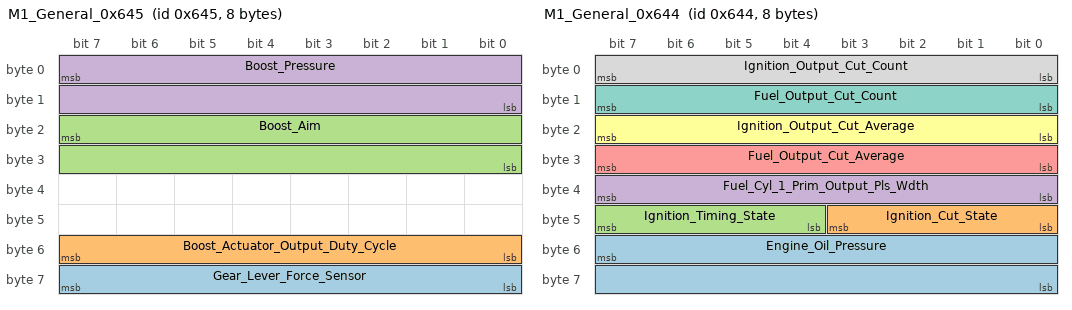
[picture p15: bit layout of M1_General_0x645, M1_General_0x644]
BO_ 1605 M1_General_0x645: 8 Vector__XXX
 SG_ Gear_Lever_Force_Sensor : 63|8@0- (5,0) [-635|635] "N" Vector__XXX
 SG_ Boost_Actuator_Output_Duty_Cycle : 55|8@0+ (1,0) [0|100] "%" Vector__XXX
 SG_ Boost_Aim : 23|16@0+ (0.1,0) [0|1000] "kPa" Vector__XXX
 SG_ Boost_Pressure : 7|16@0- (0.1,0) [0|1000] "kPa" Vector__XXX

BO_ 1604 M1_General_0x644: 8 Vector__XXX
 SG_ Engine_Oil_Pressure : 55|16@0+ (0.1,0) [0|0] "kPa" Vector__XXX
 SG_ Ignition_Cut_State : 43|4@0+ (1,0) [0|15] "" Vector__XXX
 SG_ Ignition_Timing_State : 47|4@0+ (1,0) [0|15] "" Vector__XXX
 SG_ Fuel_Cyl_1_Prim_Output_Pls_Wdth : 39|8@0+ (0.1,0) [0|25.5] "ms" Vector__XXX
 SG_ Fuel_Output_Cut_Average : 31|8@0+ (1,0) [0|100] "%" Vector__XXX
 SG_ Ignition_Output_Cut_Average : 23|8@0+ (1,0) [0|100] "%" Vector__XXX
 SG_ Fuel_Output_Cut_Count : 15|8@0+ (1,0) [0|255] "" Vector__XXX
 SG_ Ignition_Output_Cut_Count : 7|8@0+ (1,0) [0|255] "" Vector__XXX

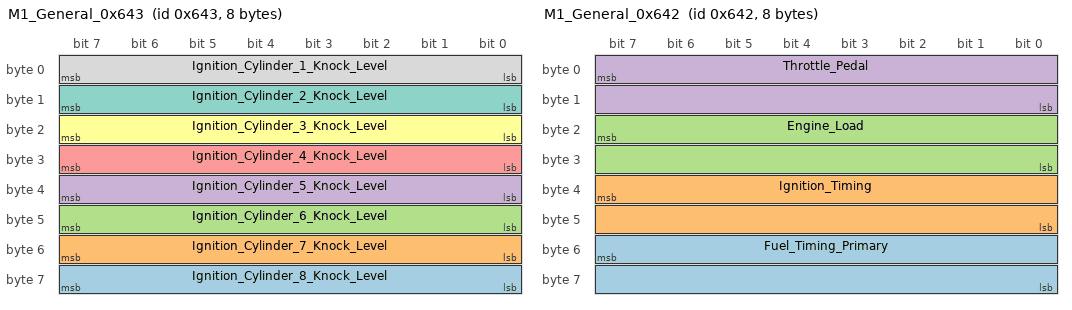
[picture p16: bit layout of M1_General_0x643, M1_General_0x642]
BO_ 1603 M1_General_0x643: 8 Vector__XXX
 SG_ Ignition_Cylinder_8_Knock_Level : 63|8@0+ (1,0) [0|200] "%" Vector__XXX
 SG_ Ignition_Cylinder_7_Knock_Level : 55|8@0+ (1,0) [0|200] "%" Vector__XXX
 SG_ Ignition_Cylinder_6_Knock_Level : 47|8@0+ (1,0) [0|200] "%" Vector__XXX
 SG_ Ignition_Cylinder_5_Knock_Level : 39|8@0+ (1,0) [0|200] "%" Vector__XXX
 SG_ Ignition_Cylinder_4_Knock_Level : 31|8@0+ (1,0) [0|200] "%" Vector__XXX
 SG_ Ignition_Cylinder_3_Knock_Level : 23|8@0+ (1,0) [0|200] "%" Vector__XXX
 SG_ Ignition_Cylinder_2_Knock_Level : 15|8@0+ (1,0) [0|200] "%" Vector__XXX
 SG_ Ignition_Cylinder_1_Knock_Level : 7|8@0+ (1,0) [0|200] "%" Vector__XXX

BO_ 1602 M1_General_0x642: 8 Vector__XXX
 SG_ Fuel_Timing_Primary : 55|16@0- (0.1,0) [-720|720] "deg" Vector__XXX
 SG_ Ignition_Timing : 39|16@0- (0.1,0) [-100|100] "deg" Vector__XXX
 SG_ Engine_Load : 23|16@0+ (1,0) [0|1000] "mg" Vector__XXX
 SG_ Throttle_Pedal : 7|16@0+ (0.1,0) [0|100] "%" Vector__XXX

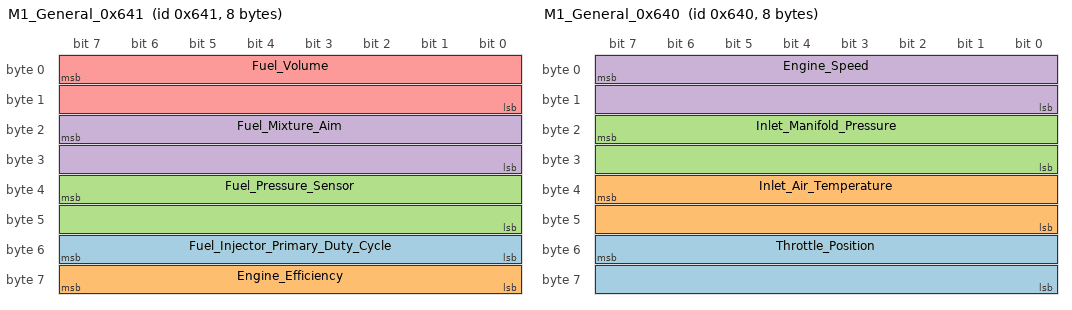
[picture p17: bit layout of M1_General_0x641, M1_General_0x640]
BO_ 1601 M1_General_0x641: 8 Vector__XXX
 SG_ Fuel_Injector_Primary_Duty_Cycle : 55|8@0+ (1,0) [0|100] "%" Vector__XXX
 SG_ Engine_Efficiency : 63|8@0+ (1,0) [0|160] "%" Vector__XXX
 SG_ Fuel_Pressure_Sensor : 39|16@0+ (0.1,0) [0|1000] "kPa" Vector__XXX
 SG_ Fuel_Mixture_Aim : 23|16@0+ (0.01,0) [0|2] "LA" Vector__XXX
 SG_ Fuel_Volume : 7|16@0+ (1,0) [0|500] "ul" Vector__XXX

BO_ 1600 M1_General_0x640: 8 Vector__XXX
 SG_ Throttle_Position : 55|16@0+ (0.1,0) [0|100] "%" Vector__XXX
 SG_ Inlet_Air_Temperature : 39|16@0- (0.1,0) [-40|120] "C" Vector__XXX
 SG_ Inlet_Manifold_Pressure : 23|16@0+ (0.1,0) [0|500] "kPa" Vector__XXX
 SG_ Engine_Speed : 7|16@0+ (1,0) [0|16000] "RPM" Vector__XXX

CM_ BO_ 3221225472 "This is a message for not used signals, created by Vector CANdb++ DBC OLE DB Provider.";
CM_ SG_ 1649 Alt_Fuel_Timing_Secondary "-ve means BTDC";
CM_ SG_ 1649 Alt_Fuel_Timing_Primary "-ve means BTDC";
CM_ SG_ 1626 Ignition_Cyl_12_Trim_Knock "+ve means ATDC";
CM_ SG_ 1626 Ignition_Cyl_11_Trim_Knock "+ve means ATDC";
CM_ SG_ 1626 Ignition_Cyl_10_Trim_Knock "+ve means ATDC";
CM_ SG_ 1626 Ignition_Cyl_9_Trim_Knock "+ve means ATDC";
CM_ BO_ 1620 "Message only sent by direct injection ECU's";
CM_ BO_ 1619 "Message only sent by direct injection ECU's";
CM_ SG_ 1618 Fuel_Timing_Secondary "-ve means BTDC";
CM_ SG_ 1615 Engine_Run_Time_Total "Does not roll over";
CM_ SG_ 1612 ECU_Up_Time "Does not roll over";
CM_ SG_ 1612 Engine_Run_Time "Does not roll over";
CM_ SG_ 1611 Ignition_Cyl_8_Trim_Knock "+ve means ATDC";
CM_ SG_ 1611 Ignition_Cyl_7_Trim_Knock "+ve means ATDC";
CM_ SG_ 1611 Ignition_Cyl_6_Trim_Knock "+ve means ATDC";
CM_ SG_ 1611 Ignition_Cyl_5_Trim_Knock "+ve means ATDC";
CM_ SG_ 1611 Ignition_Cyl_4_Trim_Knock "+ve means ATDC";
CM_ SG_ 1611 Ignition_Cyl_3_Trim_Knock "+ve means ATDC";
CM_ SG_ 1611 Ignition_Cyl_2_Trim_Knock "+ve means ATDC";
CM_ SG_ 1611 Ignition_Cyl_1_Trim_Knock "+ve means ATDC";
CM_ SG_ 1607 Exhaust_Camshaft_Bank_2_Position "-ve means BTDC";
CM_ SG_ 1607 Exhaust_Camshaft_Bank_1_Position "-ve means BTDC";
CM_ SG_ 1607 Exhaust_Camshaft_Aim "-ve means BTDC";
CM_ SG_ 1606 Inlet_Camshaft_Bank_2_Position "-ve means BTDC";
CM_ SG_ 1606 Inlet_Camshaft_Bank_1_Position "-ve means BTDC";
CM_ SG_ 1606 Inlet_Camshaft_Aim "-ve means BTDC";
CM_ SG_ 1604 Fuel_Output_Cut_Average "Rolls over at 255";
CM_ SG_ 1604 Ignition_Output_Cut_Average "Rolls over at 255
";
CM_ SG_ 1604 Fuel_Output_Cut_Count "Rolls over at 255
";
CM_ SG_ 1604 Ignition_Output_Cut_Count "Rolls over at 255
";
CM_ SG_ 1602 Fuel_Timing_Primary "-ve means BTDC";
CM_ SG_ 1602 Ignition_Timing "-ve means BTDC";
VAL_ 1650 Alt_Fuel_Pump_State 0 "Off" 1 "On" 2 "Prime" 3 "Hold" 4 "Test" ;
VAL_ 1648 Fuel_Composition_Sensor_Diag -3 "CommunicationsTimeout" -2 "LowFault" -1 "HighFault" 0 "NotinUse" 1 "OK" 2 "LowWarning" 3 "HighWarning" 4 "Translation_Minimum" 5 "Translation_Maximum" ;
VAL_ 1648 Alternative_Fuel_Mode 2 "Secondary Fuel" 1 "Flex Fuel" 0 "Not in Use" ;
VAL_ 1628 Driver_Rotary_Switch_8 -1 "Default" 1 "One" 2 "Two" 3 "Three" 4 "Four" 5 "Five" 6 "Six" 7 "Seven" 8 "Eight" 9 "Nine" 0 "Zero" ;
VAL_ 1628 Driver_Rotary_Switch_7 -1 "Default" 1 "One" 2 "Two" 3 "Three" 4 "Four" 5 "Five" 6 "Six" 7 "Seven" 8 "Eight" 9 "Nine" 0 "Zero" ;
VAL_ 1616 Driver_Rotary_Switch_6 -1 "Default" 1 "One" 2 "Two" 3 "Three" 4 "Four" 5 "Five" 6 "Six" 7 "Seven" 8 "Eight" 9 "Nine" 0 "Zero" ;
VAL_ 1616 Driver_Rotary_Switch_5 -1 "Default" 1 "One" 2 "Two" 3 "Three" 4 "Four" 5 "Five" 6 "Six" 7 "Seven" 8 "Eight" 9 "Nine" 0 "Zero" ;
VAL_ 1616 Driver_Rotary_Switch_4 -1 "Default" 1 "One" 2 "Two" 3 "Three" 4 "Four" 5 "Five" 6 "Six" 7 "Seven" 8 "Eight" 9 "Nine" 0 "Zero" ;
VAL_ 1616 Driver_Rotary_Switch_3 -1 "Default" 1 "One" 2 "Two" 3 "Three" 4 "Four" 5 "Five" 6 "Six" 7 "Seven" 8 "Eight" 9 "Nine" 0 "Zero" ;
VAL_ 1616 Driver_Rotary_Switch_2 -1 "Default" 1 "One" 2 "Two" 3 "Three" 4 "Four" 5 "Five" 6 "Six" 7 "Seven" 8 "Eight" 9 "Nine" 0 "Zero" ;
VAL_ 1616 Driver_Rotary_Switch_1 -1 "Default" 1 "One" 2 "Two" 3 "Three" 4 "Four" 5 "Five" 6 "Six" 7 "Seven" 8 "Eight" 9 "Nine" 0 "Zero" ;
VAL_ 281 Brake_State -1 "Sensor_Fault" 0 "Unknown" 1 "Off" 2 "On" ;
VAL_ 1614 Fuel_Cut_State 0 "None" 1 "Anti_Lag" 2 "Engine_Overrun" 3 "Flooded_Throttle_Position" 4 "Boost_Control_Diagnostic" 5 "Gear_Shift" 6 "Engine_Speed_Limit" ;
VAL_ 1614 Brake_State -1 "Sensor_Fault" 0 "Unknown" 1 "Off" 2 "On" ;
VAL_ 1614 Fuel_Closed_Loop_Diagnostic -1 "Control_Failure" 0 "Sensor_Unavailable" 1 "OK" 2 "Single_Sensor" ;
VAL_ 1614 Boost_Control_Diagnostic -1 "Maximum" 0 "Not_in_Use" 1 "Off" 2 "Active" 3 "Under_Margin" 4 "Over_Margin" 5 "Test" ;
VAL_ 1614 Launch_Diagnostic 0 "Not_in_Use" 1 "OK" 2 "Exhaust_Temperature_High" 3 "Coolant_Temperature_High" ;
VAL_ 1614 Anti_Lag_Diagnostic 3 "Exhaust_Temperature_High" 2 "Time_Limit" 4 "Coolant_Temperature_High" 0 "Not_in_Use" 1 "OK" ;
VAL_ 1613 Engine_Speed_Limit_State 0 "Maximum" 2 "Throttle_Servo_Fault" 3 "Coolant_Temperature" 7 "Engine_Output_Test" 4 "Traction_Control" 5 "Launch" 6 "Vehicle_Speed_Limit" 1 "Engine_Load_Average" 8 "Anti_Lag" 10 "Coolant_Temperature_Warning" 11 "Coolant_Pressure_Warning" 12 "Engine_Speed_Warning" 13 "Engine_Oil_Temperature_Warning" 14 "Engine_Oil_Pressure_Warning" 15 "Engine_Crankcase_Pressure_Warning" 16 "Fuel_Pressure_Warning" 9 "Gear_Shift" 17 "Inlet_Air_Temperature_Warning" 18 "Exhaust_Lambda_Warning" 19 "Exhaust_Temperature_Warning" 20 "Experimental_Reference_Mode" 21 "Alternative_Fuel_Pressure_Warning" 22 "Boost_Servo_Fault" ;
VAL_ 1613 Fuel_State 5 "Cut_Cylinder_2_Test" 1 "Enabled" 2 "Cut_Bank_1_Test" 3 "Cut_Bank_2_Test" 4 "Cut_Cylinder_1_Test" 6 "Cut_Cylinder_3_Test" 7 "Cut_Cylinder_4_Test" 8 "Cut_Cylinder_5_Test" 9 "Cut_Cylinder_6_Test" 10 "Cut_Cylinder_7_Test" 11 "Cut_Cylinder_8_Test" 12 "Cut_Cylinder_9_Test" 13 "Cut_Cylinder_10_Test" 14 "Cut_Cylinder_11_Test" 15 "Cut_Cylinder_12_Test" 0 "Disabled" ;
VAL_ 1613 Gear -2 "Default" -1 "Reverse" 0 "Neutral" 1 "First" 2 "Second" 3 "Third" 4 "Fourth" 5 "Fifth" 6 "Sixth" 7 "Seventh" ;
VAL_ 1613 Engine_Speed_Reference_State 0 "Open" 1 "Initialise" 2 "Stall" 3 "First Edge" 4 "First Period" 5 "Search" 6 "Pattern Lock" 7 "Cycle Lock" 8 "Error" 9 "Exit" 10 "Test" ;
VAL_ 1613 Fuel_Closed_Loop_State -1 "Fault" 0 "Disabled" 1 "Shutdown" 2 "Wait" 3 "Sample" ;
VAL_ 1613 Throttle_Aim_State 5 "Test" 1 "Idle" 0 "Pedal" 2 "Anti_Lag" 3 "Throttle_Limit" 4 "Gear_Shift" ;
VAL_ 1613 Knock_State 0 "Disabled" 1 "Enabled" 2 "Transient" ;
VAL_ 1613 Engine_Overrun_State 0 "Disabled" 1 "Retard_Ignition" 2 "Enabled" 3 "Advance_Ignition" ;
VAL_ 1613 Boost_Aim_State 0 "Normal" 1 "Anti_Lag" 2 "Launch" ;
VAL_ 1613 Launch_State 0 "Disabled" 1 "Enabled" ;
VAL_ 1613 Anti_Lag_State 1 "Armed" 0 "Disabled" 2 "Enabled" 3 "Recover" ;
VAL_ 1613 Fuel_Pump_State 0 "Off" 1 "On" 2 "Prime" 3 "Hold" 4 "Test" ;
VAL_ 1613 Engine_State 0 "Startup" 1 "Stop" 2 "Run" 3 "Crank" ;
VAL_ 1612 Warning_Source 23 "Exhaust_Temperature_Diagnostic" 35 "Boost_Control_Diagnostic" 36 "Coolant_Pressure_Sensor_Diagnostic" 21 "Exhaust_Lambda_Bank_1_Collector_Diagnostic" 24 "Throttle_Pedal_Sensor_Diagnostic" 25 "Throttle_Position_Sensor_Diagnostic" 26 "Throttle_Servo_Bank_1_Position_Sensor_Diagnostic" 27 "Throttle_Servo_Bank_2_Position_Sensor_Diagnostic" 37 "Inlet_Camshaft_Bank_1_Position_Diagnostic" 60 "Fuel_Cylinder_8_Secondary_Pin_Diagnostic" 64 "Fuel_Cylinder_12_Secondary_Pin_Diagnostic" 52 "Fuel_Cylinder_12_Primary_Pin_Diagnostic" 66 "CAN_Bus_2_Diagnostic" 65 "CAN_Bus_1_Diagnostic" 63 "Fuel_Cylinder_11_Secondary_Pin_Diagnostic" 38 "Inlet_Camshaft_Bank_2_Position_Diagnostic" 62 "Fuel_Cylinder_10_Secondary_Pin_Diagnostic" 30 "Fuel_Temperature_Sensor_Diagnostic" 17 "Brake_Vacuum_Pressure_Sensor_Diagnostic" 59 "Fuel_Cylinder_7_Secondary_Pin_Diagnostic" 18 "Inlet_Air_Temperature_Sensor_Diagnostic" 19 "Engine_Crankcase_Pressure_Sensor_Diagnostic" 20 "Engine_Oil_Temperature_Sensor_Diagnostic" 56 "Fuel_Cylinder_4_Secondary_Pin_Diagnostic" 48 "Fuel_Cylinder_8_Primary_Pin_Diagnostic" 49 "Fuel_Cylinder_9_Primary_Pin_Diagnostic" 45 "Fuel_Cylinder_5_Primary_Pin_Diagnostic" 50 "Fuel_Cylinder_10_Primary_Pin_Diagnostic" 51 "Fuel_Cylinder_11_Primary_Pin_Diagnostic" 57 "Fuel_Cylinder_5_Secondary_Pin_Diagnostic" 58 "Fuel_Cylinder_6_Secondary_Pin_Diagnostic" 14 "Engine_Oil_Pressure_Sensor_Diagnostic" 11 "Coolant_Pressure_Warning" 13 "Inlet_Manifold_Pressure_Sensor_Diagnostic" 12 "Engine_Speed_Warning" 28 "Boost_Pressure_Sensor_Diagnostic" 39 "Exhaust_Camshaft_Bank_1_Position_Diagnostic" 67 "CAN_Bus_3_Diagnostic" 70 "GPS_Diagnostic" 41 "Fuel_Cylinder_1_Primary_Pin_Diagnostic" 42 "Fuel_Cylinder_2_Primary_Pin_Diagnostic" 43 "Fuel_Cylinder_3_Primary_Pin_Diagnostic" 44 "Fuel_Cylinder_4_Primary_Pin_Diagnostic" 33 "Throttle_Servo_Bank_1_Diagnostic" 34 "Throttle_Servo_Bank_2_Diagnostic" 32 "Fuel_Closed_Loop_Diagnostic" 31 "Ambient_Pressure_Sensor_Diagnostic" 53 "Fuel_Cylinder_1_Secondary_Pin_Diagnostic" 55 "Fuel_Cylinder_3_Secondary_Pin_Diagnostic" 22 "Exhaust_Lambda_Bank_2_Collector_Diagnostic" 0 "None" 16 "Fuel_Pressure_Sensor_Diagnostic" 54 "Fuel_Cylinder_2_Secondary_Pin_Diagnostic" 2 "Knock_Warning" 3 "Engine_Crankcase_Pressure_Warning" 4 "Fuel_Pressure_Warning" 6 "Coolant_Temperature_Warning" 7 "Inlet_Air_Temperature_Warning" 8 "Engine_Oil_Temperature_Warning" 61 "Fuel_Cylinder_9_Secondary_Pin_Diagnostic" 10 "Exhaust_Temperature_Warning" 9 "Exhaust_Lambda_Warning" 46 "Fuel_Cylinder_6_Primary_Pin_Diagnostic" 47 "Fuel_Cylinder_7_Primary_Pin_Diagnostic" 15 "Coolant_Temperature_Sensor_Diagnostic" 40 "Exhaust_Camshaft_Bank_2_Position_Diagnostic" 68 "RS232_Diagnostic" 69 "Engine_Speed_Reference_Diagnostic" 1 "Engine_Oil_Pressure_Warning" 71 "Engine_Speed_Reference_State" 72 "Vehicle_Acceleration_Lateral_Sensor_Diagnostic" 5 "Alternative_Fuel_Pressure_Warning" 29 "Fuel_Composition_Sensor_Diagnostic" ;
VAL_ 1604 Ignition_Cut_State 0 "None" 1 "Anti_Lag" 2 "Gear_Shift" 3 "Engine_Speed_Limit" ;
VAL_ 1604 Ignition_Timing_State 3 "Limit_Advance" 4 "Limit_Retard" 0 "Normal" 2 "Check_Timing" 1 "Cranking" 7 "Launch" 5 "Idle" 6 "Engine_Overrun" 8 "Gear_Shift" 9 "Anti_Lag" ;
